# S32K144 register map
Vendor: NXP; Series: S32K; File version: 1.6
CPU: CM4 r0p1, little endian, MPU, FPU, 4 interrupt priority bits
Registers are 32-bit, read-write, reset 0x0 unless marked. A register's access mark holds for its fields unless they carry their own. Offsets are from the block's base; [hi:lo] are bit positions; {n}, {i} and the like mark numbered series; 'fields as' and 'values as' point back to an identical list.

## CAN0 — Flex Controller Area Network module
Base 0x40024000; register names take the prefix CAN0_
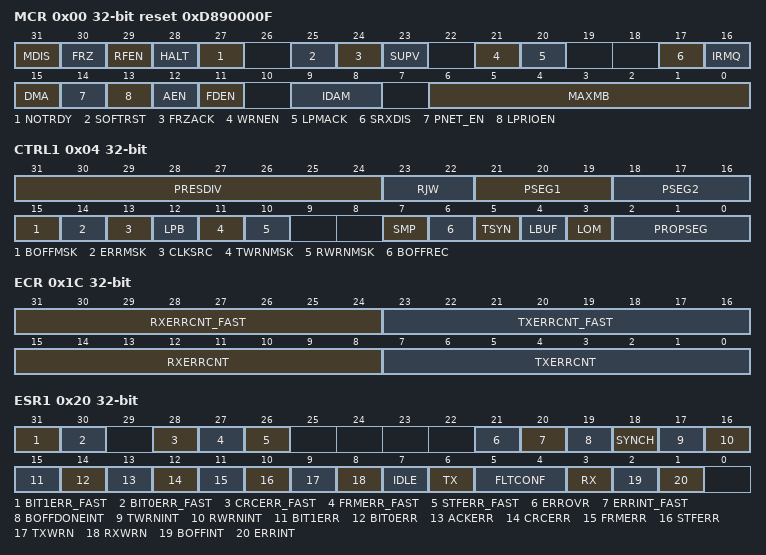
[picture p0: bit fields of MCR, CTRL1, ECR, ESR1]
0x00 MCR reset 0xD890000F — Module Configuration Register
  [31] MDIS — Module Disable
    0=Enable the FlexCAN module; 1=Disable the FlexCAN module
  [30] FRZ — Freeze Enable
    0=Not enabled to enter Freeze mode; 1=Enabled to enter Freeze mode
  [29] RFEN — Rx FIFO Enable
    0=Rx FIFO not enabled; 1=Rx FIFO enabled
  [28] HALT — Halt FlexCAN
    0=No Freeze mode request; 1=Enters Freeze mode if the FRZ bit is asserted
  [27] NOTRDY ro — FlexCAN Not Ready
    0=FlexCAN module is either in Normal mode, Listen-Only mode or Loop-Back mode
  [25] SOFTRST — Soft Reset
    0=No reset request; 1=Resets the registers affected by soft reset
  [24] FRZACK ro — Freeze Mode Acknowledge
    0=FlexCAN not in Freeze mode, prescaler running; 1=FlexCAN in Freeze mode, prescaler stopped
  [23] SUPV — Supervisor Mode
  [21] WRNEN — Warning Interrupt Enable
    0=TWRNINT and RWRNINT bits are zero, independent of the values in the error counters; 1=TWRNINT and RWRNINT bits are set when the respective error counter transitions from less than 96 to greater than or equal to 96
  [20] LPMACK ro — Low-Power Mode Acknowledge
    0=FlexCAN is not in a low-power mode; 1=FlexCAN is in a low-power mode
  [17] SRXDIS — Self Reception Disable
    0=Self reception enabled; 1=Self reception disabled
  [16] IRMQ — Individual Rx Masking And Queue Enable
    0=Individual Rx masking and queue feature are disabled. For backward compatibility with legacy applications, the reading of C/S word locks the MB even if it is EMPTY.; 1=Individual Rx masking and queue feature are enabled
  [15] DMA — DMA Enable
    0=DMA feature for RX FIFO disabled; 1=DMA feature for RX FIFO enabled
  [14] PNET_EN — Pretended Networking Enable
    0=Pretended Networking mode is disabled; 1=Pretended Networking mode is enabled
  [13] LPRIOEN — Local Priority Enable
    0=Local Priority disabled; 1=Local Priority enabled
  [12] AEN — Abort Enable
    0=Abort disabled; 1=Abort enabled
  [11] FDEN — CAN FD operation enable
    1=CAN FD is enabled. FlexCAN is able to receive and transmit messages in both CAN FD and CAN 2.0 formats.; 0=CAN FD is disabled. FlexCAN is able to receive and transmit messages in CAN 2.0 format.
  [9:8] IDAM — ID Acceptance Mode
    0=Format A: One full ID (standard and extended) per ID Filter Table element; 1=Format B: Two full standard IDs or two partial 14-bit (standard and extended) IDs per ID Filter Table element; 2=Format C: Four partial 8-bit Standard IDs per ID Filter Table element; 3=Format D: All frames rejected
  [6:0] MAXMB — Number Of The Last Message Buffer
0x04 CTRL1 — Control 1 register
  [31:24] PRESDIV — Prescaler Division Factor
  [23:22] RJW — Resync Jump Width
  [21:19] PSEG1 — Phase Segment 1
  [18:16] PSEG2 — Phase Segment 2
  [15] BOFFMSK — Bus Off Interrupt Mask
    0=Bus Off interrupt disabled; 1=Bus Off interrupt enabled
  [14] ERRMSK — Error Interrupt Mask
    0=Error interrupt disabled; 1=Error interrupt enabled
  [13] CLKSRC — CAN Engine Clock Source
    0=The CAN engine clock source is the oscillator clock. Under this condition, the oscillator clock frequency must be lower than the bus clock.; 1=The CAN engine clock source is the peripheral clock
  [12] LPB — Loop Back Mode
    0=Loop Back disabled; 1=Loop Back enabled
  [11] TWRNMSK — Tx Warning Interrupt Mask
    0=Tx Warning Interrupt disabled; 1=Tx Warning Interrupt enabled
  [10] RWRNMSK — Rx Warning Interrupt Mask
    0=Rx Warning Interrupt disabled; 1=Rx Warning Interrupt enabled
  [7] SMP — CAN Bit Sampling
    0=Just one sample is used to determine the bit value; 1=Three samples are used to determine the value of the received bit: the regular one (sample point) and 2 preceding samples; a majority rule is used
  [6] BOFFREC — Bus Off Recovery
    0=Automatic recovering from Bus Off state enabled; 1=Automatic recovering from Bus Off state disabled
  [5] TSYN — Timer Sync
    0=Timer Sync feature disabled; 1=Timer Sync feature enabled
  [4] LBUF — Lowest Buffer Transmitted First
    0=Buffer with highest priority is transmitted first; 1=Lowest number buffer is transmitted first
  [3] LOM — Listen-Only Mode
    0=Listen-Only mode is deactivated; 1=FlexCAN module operates in Listen-Only mode
  [2:0] PROPSEG — Propagation Segment
0x08 TIMER — Free Running Timer
  [15:0] TIMER — Timer Value
0x10 RXMGMASK reset not defined — Rx Mailboxes Global Mask Register
  [31:0] MG — Rx Mailboxes Global Mask Bits
0x14 RX14MASK reset not defined
  [31:0] RX14M — Rx Buffer 14 Mask Bits
0x18 RX15MASK reset not defined
  [31:0] RX15M — Rx Buffer 15 Mask Bits
0x1C ECR — Error Counter
  [31:24] RXERRCNT_FAST — Receive Error Counter for fast bits
  [23:16] TXERRCNT_FAST — Transmit Error Counter for fast bits
  [15:8] RXERRCNT — Receive Error Counter
  [7:0] TXERRCNT — Transmit Error Counter
0x20 ESR1 — Error and Status 1 register
  [31] BIT1ERR_FAST ro — Bit1 Error in the Data Phase of CAN FD frames with the BRS bit set
    0=No such occurrence; 1=At least one bit sent as recessive is received as dominant
  [30] BIT0ERR_FAST ro — Bit0 Error in the Data Phase of CAN FD frames with the BRS bit set
    0=No such occurrence; 1=At least one bit sent as dominant is received as recessive
  [28] CRCERR_FAST ro — Cyclic Redundancy Check Error in the CRC field of CAN FD frames with the BRS bit set
    0=No such occurrence; 1=A CRC error occurred since last read of this register
  [27] FRMERR_FAST ro — Form Error in the Data Phase of CAN FD frames with the BRS bit set
    0=No such occurrence; 1=A Form Error occurred since last read of this register
  [26] STFERR_FAST ro — Stuffing Error in the Data Phase of CAN FD frames with the BRS bit set
    0=No such occurrence; 1=A Stuffing Error occurred since last read of this register
  [21] ERROVR — Error Overrun bit
    0=Overrun has not occurred; 1=Overrun has occurred
  [20] ERRINT_FAST — Error Interrupt for errors detected in the Data Phase of CAN FD frames with the BRS bit set
    0=No such occurrence; 1=Indicates setting of any Error Bit detected in the Data Phase of CAN FD frames with the BRS bit set
  [19] BOFFDONEINT — Bus Off Done Interrupt
    0=No such occurrence; 1=FlexCAN module has completed Bus Off process
  [18] SYNCH ro — CAN Synchronization Status
    0=FlexCAN is not synchronized to the CAN bus; 1=FlexCAN is synchronized to the CAN bus
  [17] TWRNINT — Tx Warning Interrupt Flag
    0=No such occurrence; 1=The Tx error counter transitioned from less than 96 to greater than or equal to 96
  [16] RWRNINT — Rx Warning Interrupt Flag
    0=No such occurrence; 1=The Rx error counter transitioned from less than 96 to greater than or equal to 96
  [15] BIT1ERR ro — Bit1 Error
    values as BIT1ERR_FAST
  [14] BIT0ERR ro — Bit0 Error
    values as BIT0ERR_FAST
  [13] ACKERR ro — Acknowledge Error
    0=No such occurrence; 1=An ACK error occurred since last read of this register
  [12] CRCERR ro — Cyclic Redundancy Check Error
    values as CRCERR_FAST
  [11] FRMERR ro — Form Error
    values as FRMERR_FAST
  [10] STFERR ro — Stuffing Error
    values as STFERR_FAST
  [9] TXWRN ro — TX Error Warning
    0=No such occurrence; 1=TXERRCNT is greater than or equal to 96
  [8] RXWRN ro — Rx Error Warning
    0=No such occurrence; 1=RXERRCNT is greater than or equal to 96
  [7] IDLE ro
    0=No such occurrence; 1=CAN bus is now IDLE
  [6] TX ro — FlexCAN In Transmission
    0=FlexCAN is not transmitting a message; 1=FlexCAN is transmitting a message
  [5:4] FLTCONF ro — Fault Confinement State
    0=Error Active; 1=Error Passive; 0b1x=Bus Off
  [3] RX ro — FlexCAN In Reception
    0=FlexCAN is not receiving a message; 1=FlexCAN is receiving a message
  [2] BOFFINT — Bus Off Interrupt
    0=No such occurrence; 1=FlexCAN module entered Bus Off state
  [1] ERRINT — Error Interrupt
    0=No such occurrence; 1=Indicates setting of any Error Bit in the Error and Status Register
0x28 IMASK1 — Interrupt Masks 1 register
  [31:0] BUF31TO0M — Buffer MB i Mask
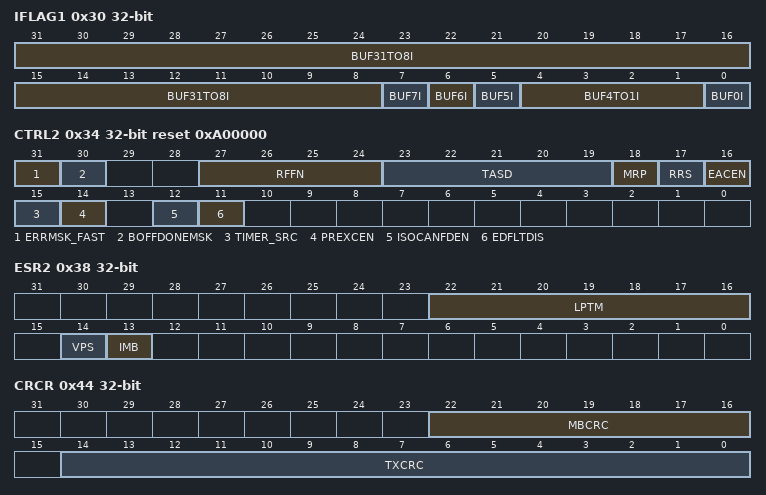
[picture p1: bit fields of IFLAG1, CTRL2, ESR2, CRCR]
0x30 IFLAG1 — Interrupt Flags 1 register
  [31:8] BUF31TO8I — Buffer MBi Interrupt
  [7] BUF7I — Buffer MB7 Interrupt Or "Rx FIFO Overflow"
    0=No occurrence of MB7 completing transmission/reception when MCR[RFEN]=0, or of Rx FIFO overflow when MCR[RFEN]=1; 1=MB7 completed transmission/reception when MCR[RFEN]=0, or Rx FIFO overflow when MCR[RFEN]=1
  [6] BUF6I — Buffer MB6 Interrupt Or "Rx FIFO Warning"
    0=No occurrence of MB6 completing transmission/reception when MCR[RFEN]=0, or of Rx FIFO almost full when MCR[RFEN]=1; 1=MB6 completed transmission/reception when MCR[RFEN]=0, or Rx FIFO almost full when MCR[RFEN]=1
  [5] BUF5I — Buffer MB5 Interrupt Or "Frames available in Rx FIFO"
    0=No occurrence of MB5 completing transmission/reception when MCR[RFEN]=0, or of frame(s) available in the FIFO, when MCR[RFEN]=1; 1=MB5 completed transmission/reception when MCR[RFEN]=0, or frame(s) available in the Rx FIFO when MCR[RFEN]=1. It generates a DMA request in case of MCR[RFEN] and MCR[DMA] are enabled.
  [4:1] BUF4TO1I — Buffer MB i Interrupt Or "reserved"
  [0] BUF0I — Buffer MB0 Interrupt Or Clear FIFO bit
    0=The corresponding buffer has no occurrence of successfully completed transmission or reception when MCR[RFEN]=0; 1=The corresponding buffer has successfully completed transmission or reception when MCR[RFEN]=0
0x34 CTRL2 reset 0xA00000 — Control 2 register
  [31] ERRMSK_FAST — Error Interrupt Mask for errors detected in the Data Phase of fast CAN FD frames
    0=ERRINT_FAST Error interrupt disabled; 1=ERRINT_FAST Error interrupt enabled
  [30] BOFFDONEMSK — Bus Off Done Interrupt Mask
    0=Bus Off Done interrupt disabled; 1=Bus Off Done interrupt enabled
  [27:24] RFFN — Number Of Rx FIFO Filters
  [23:19] TASD — Tx Arbitration Start Delay
  [18] MRP — Mailboxes Reception Priority
    0=Matching starts from Rx FIFO and continues on Mailboxes; 1=Matching starts from Mailboxes and continues on Rx FIFO
  [17] RRS — Remote Request Storing
    0=Remote Response Frame is generated; 1=Remote Request Frame is stored
  [16] EACEN — Entire Frame Arbitration Field Comparison Enable For Rx Mailboxes
    0=Rx Mailbox filter's IDE bit is always compared and RTR is never compared despite mask bits; 1=Enables the comparison of both Rx Mailbox filter's IDE and RTR bit with their corresponding bits within the incoming frame. Mask bits do apply.
  [15] TIMER_SRC — Timer Source
    0=The Free Running Timer is clocked by the CAN bit clock, which defines the baud rate on the CAN bus; 1=The Free Running Timer is clocked by an external time tick. The period can be either adjusted to be equal to the baud rate on the CAN bus, or a different value as required. See the device specific section for details about the external time tick.
  [14] PREXCEN — Protocol Exception Enable
    0=Protocol Exception is disabled; 1=Protocol Exception is enabled
  [12] ISOCANFDEN — ISO CAN FD Enable
    0=FlexCAN operates using the non-ISO CAN FD protocol; 1=FlexCAN operates using the ISO CAN FD protocol (ISO 11898-1)
  [11] EDFLTDIS — Edge Filter Disable
    0=Edge Filter is enabled; 1=Edge Filter is disabled
0x38 ESR2 ro — Error and Status 2 register
  [22:16] LPTM — Lowest Priority Tx Mailbox
  [14] VPS — Valid Priority Status
    0=Contents of IMB and LPTM are invalid; 1=Contents of IMB and LPTM are valid
  [13] IMB — Inactive Mailbox
    0=If ESR2[VPS] is asserted, the ESR2[LPTM] is not an inactive Mailbox; 1=If ESR2[VPS] is asserted, there is at least one inactive Mailbox. LPTM content is the number of the first one.
0x44 CRCR ro — CRC Register
  [22:16] MBCRC — CRC Mailbox
  [14:0] TXCRC — Transmitted CRC value
0x48 RXFGMASK reset not defined — Rx FIFO Global Mask register
  [31:0] FGM — Rx FIFO Global Mask Bits
0x4C RXFIR ro reset not defined — Rx FIFO Information Register
  [8:0] IDHIT — Identifier Acceptance Filter Hit Indicator
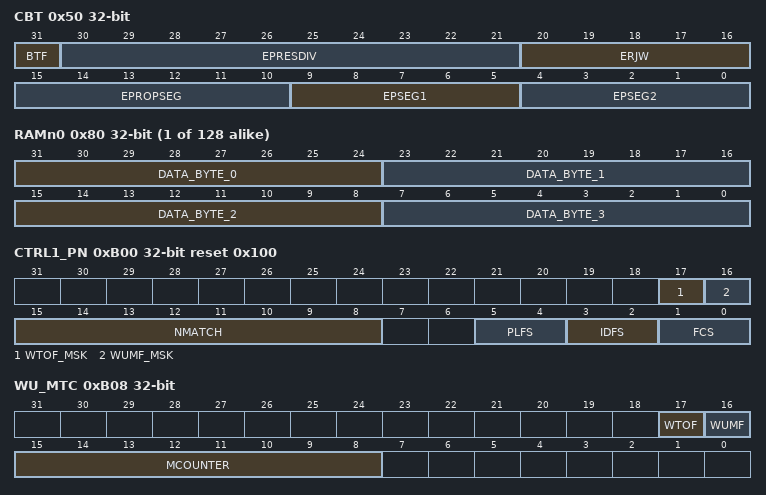
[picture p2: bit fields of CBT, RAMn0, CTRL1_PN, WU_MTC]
0x50 CBT — CAN Bit Timing Register
  [31] BTF — Bit Timing Format Enable
    0=Extended bit time definitions disabled; 1=Extended bit time definitions enabled
  [30:21] EPRESDIV — Extended Prescaler Division Factor
  [20:16] ERJW — Extended Resync Jump Width
  [15:10] EPROPSEG — Extended Propagation Segment
  [9:5] EPSEG1 — Extended Phase Segment 1
  [4:0] EPSEG2 — Extended Phase Segment 2
{0x80+4i} RAMn{i} (i=0..127) — Embedded RAM
  [31-8n:24-8n] DATA_BYTE_{n} (n=0..3) — Data byte {n} of Rx/Tx frame.
{0x880+4i} RXIMR{i} reset not defined (i=0..31) — Rx Individual Mask Registers
  [31:0] MI — Individual Mask Bits
0xB00 CTRL1_PN reset 0x100 — Pretended Networking Control 1 Register
  [17] WTOF_MSK — Wake Up by Timeout Flag Mask Bit
    0=Timeout wake up event is disabled; 1=Timeout wake up event is enabled
  [16] WUMF_MSK — Wake Up by Match Flag Mask Bit
    0=Wake up match event is disabled; 1=Wake up match event is enabled
  [15:8] NMATCH — Number of Messages Matching the Same Filtering Criteria
    1=Received message must match the predefined filtering criteria for ID and/or PL once before generating a wake up event; 2=Received message must match the predefined filtering criteria for ID and/or PL twice before generating a wake up event; 255=Received message must match the predefined filtering criteria for ID and/or PL 255 times before generating a wake up event
  [5:4] PLFS — Payload Filtering Selection
    0=Match upon a payload contents against an exact target value; 1=Match upon a payload value greater than or equal to a specified target value; 2=Match upon a payload value smaller than or equal to a specified target value; 3=Match upon a payload value inside a range, greater than or equal to a specified lower limit and smaller than or equal a specified upper limit
  [3:2] IDFS — ID Filtering Selection
    0=Match upon a ID contents against an exact target value; 1=Match upon a ID value greater than or equal to a specified target value; 2=Match upon a ID value smaller than or equal to a specified target value; 3=Match upon a ID value inside a range, greater than or equal to a specified lower limit and smaller than or equal a specified upper limit
  [1:0] FCS — Filtering Combination Selection
    0=Message ID filtering only; 1=Message ID filtering and payload filtering; 2=Message ID filtering occurring a specified number of times; 3=Message ID filtering and payload filtering a specified number of times
0xB04 CTRL2_PN — Pretended Networking Control 2 Register
  [15:0] MATCHTO — Timeout for No Message Matching the Filtering Criteria
0xB08 WU_MTC — Pretended Networking Wake Up Match Register
  [17] WTOF — Wake Up by Timeout Flag Bit
    0=No wake up by timeout event detected; 1=Wake up by timeout event detected
  [16] WUMF — Wake Up by Match Flag Bit
    0=No wake up by match event detected; 1=Wake up by match event detected
  [15:8] MCOUNTER ro — Number of Matches while in Pretended Networking
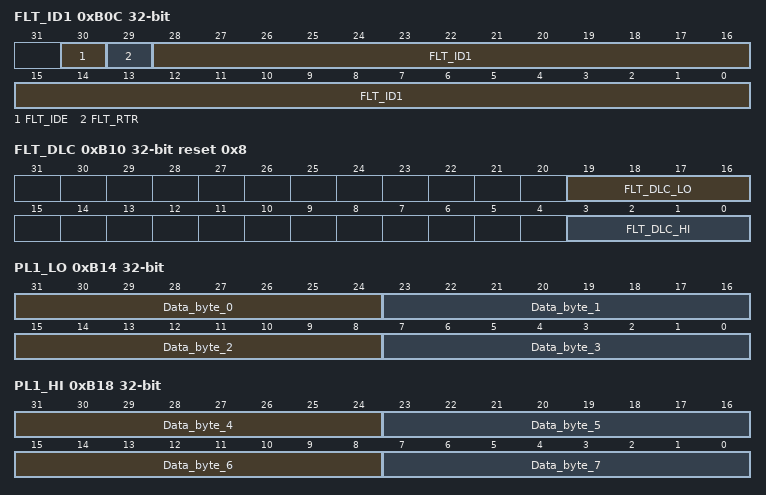
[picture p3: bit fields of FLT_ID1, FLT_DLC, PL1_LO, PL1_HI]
0xB0C FLT_ID1 — Pretended Networking ID Filter 1 Register
  [30] FLT_IDE — ID Extended Filter
    0=Accept standard frame format; 1=Accept extended frame format
  [29] FLT_RTR — Remote Transmission Request Filter
    0=Reject remote frame (accept data frame); 1=Accept remote frame
  [28:0] FLT_ID1 — ID Filter 1 for Pretended Networking filtering
0xB10 FLT_DLC reset 0x8 — Pretended Networking DLC Filter Register
  [19:16] FLT_DLC_LO — Lower Limit for Length of Data Bytes Filter
  [3:0] FLT_DLC_HI — Upper Limit for Length of Data Bytes Filter
0xB14 PL1_LO — Pretended Networking Payload Low Filter 1 Register
  [31-8n:24-8n] Data_byte_{n} (n=0..3) — Payload Filter 1 low order bits for Pretended Networking payload filtering corresponding to the data byte {n}.
0xB18 PL1_HI — Pretended Networking Payload High Filter 1 Register
  [63-8n:56-8n] Data_byte_{n} (n=4..7) — Payload Filter 1 high order bits for Pretended Networking payload filtering corresponding to the data byte {n}.
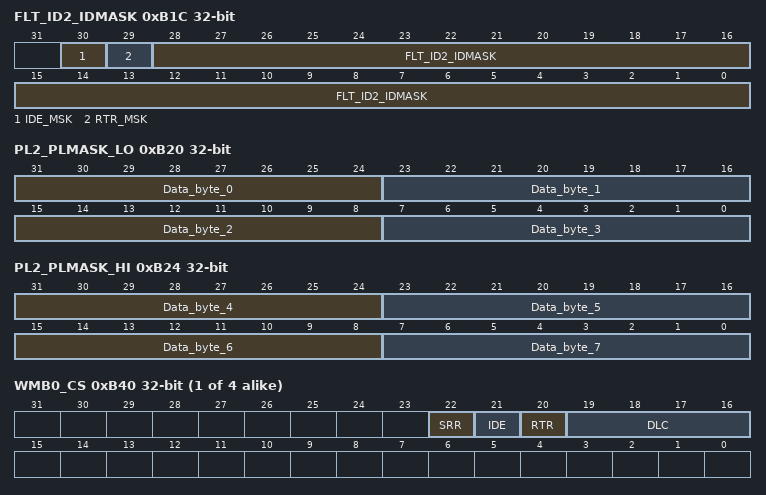
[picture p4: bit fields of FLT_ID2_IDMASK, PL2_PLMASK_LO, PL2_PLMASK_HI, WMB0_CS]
0xB1C FLT_ID2_IDMASK — Pretended Networking ID Filter 2 Register / ID Mask Register
  [30] IDE_MSK — ID Extended Mask Bit
    0=The corresponding bit in the filter is "don't care"; 1=The corresponding bit in the filter is checked
  [29] RTR_MSK — Remote Transmission Request Mask Bit
    values as IDE_MSK
  [28:0] FLT_ID2_IDMASK — ID Filter 2 for Pretended Networking Filtering / ID Mask Bits for Pretended Networking ID Filtering
0xB20 PL2_PLMASK_LO — Pretended Networking Payload Low Filter 2 Register / Payload Low Mask Register
  [31-8n:24-8n] Data_byte_{n} (n=0..3) — Payload Filter 2 low order bits / Payload Mask low order bits for Pretended Networking payload filtering corresponding to the data byte {n}.
0xB24 PL2_PLMASK_HI — Pretended Networking Payload High Filter 2 low order bits / Payload High Mask Register
  [63-8n:56-8n] Data_byte_{n} (n=4..7) — Payload Filter 2 high order bits / Payload Mask high order bits for Pretended Networking payload filtering corresponding to the data byte {n}.
{0xB40+0x10*i} WMB{i}_CS ro (i=0..3) — Wake Up Message Buffer Register for C/S
  [22] SRR — Substitute Remote Request
  [21] IDE — ID Extended Bit
    0=Frame format is standard; 1=Frame format is extended
  [20] RTR — Remote Transmission Request Bit
    0=Frame is data one (not remote); 1=Frame is a remote one
  [19:16] DLC — Length of Data in Bytes
{0xB44+0x10*i} WMB{i}_ID ro (i=0..3) — Wake Up Message Buffer Register for ID
  [28:0] ID — Received ID under Pretended Networking mode
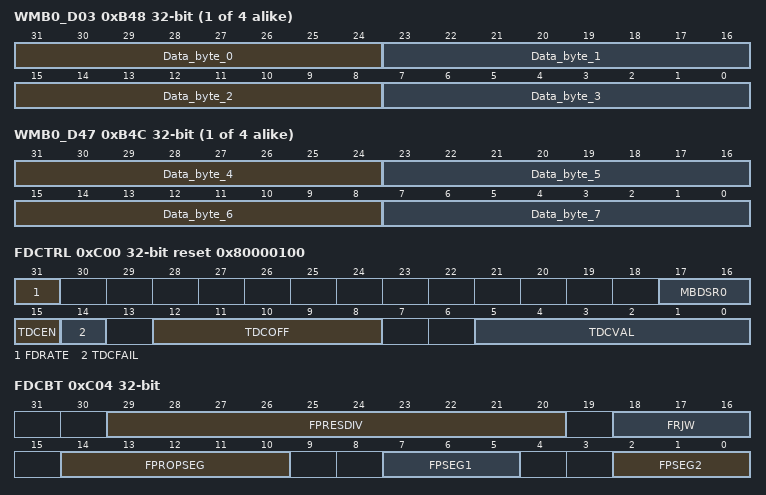
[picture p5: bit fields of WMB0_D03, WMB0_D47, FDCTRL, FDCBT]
{0xB48+0x10*i} WMB{i}_D03 ro (i=0..3) — Wake Up Message Buffer Register for Data 0-3
  [31-8n:24-8n] Data_byte_{n} (n=0..3) — Received payload corresponding to the data byte {n} under Pretended Networking mode
{0xB4C+0x10*i} WMB{i}_D47 ro (i=0..3) — Wake Up Message Buffer Register Data 4-7
  [63-8n:56-8n] Data_byte_{n} (n=4..7) — Received payload corresponding to the data byte {n} under Pretended Networking mode
0xC00 FDCTRL reset 0x80000100 — CAN FD Control Register
  [31] FDRATE — Bit Rate Switch Enable
    0=Transmit a frame in nominal rate. The BRS bit in the Tx MB has no effect.; 1=Transmit a frame with bit rate switching if the BRS bit in the Tx MB is recessive
  [17:16] MBDSR0 — Message Buffer Data Size for Region 0
    0=Selects 8 bytes per Message Buffer; 1=Selects 16 bytes per Message Buffer; 2=Selects 32 bytes per Message Buffer; 3=Selects 64 bytes per Message Buffer
  [15] TDCEN — Transceiver Delay Compensation Enable
    0=TDC is disabled; 1=TDC is enabled
  [14] TDCFAIL — Transceiver Delay Compensation Fail
    0=Measured loop delay is in range; 1=Measured loop delay is out of range
  [12:8] TDCOFF — Transceiver Delay Compensation Offset
  [5:0] TDCVAL ro — Transceiver Delay Compensation Value
0xC04 FDCBT — CAN FD Bit Timing Register
  [29:20] FPRESDIV — Fast Prescaler Division Factor
  [18:16] FRJW — Fast Resync Jump Width
  [14:10] FPROPSEG — Fast Propagation Segment
  [7:5] FPSEG1 — Fast Phase Segment 1
  [2:0] FPSEG2 — Fast Phase Segment 2
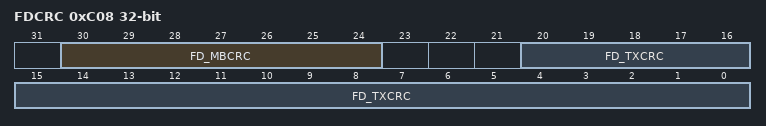
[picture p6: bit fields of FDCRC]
0xC08 FDCRC ro — CAN FD CRC Register
  [30:24] FD_MBCRC — CRC Mailbox Number for FD_TXCRC
  [20:0] FD_TXCRC — Extended Transmitted CRC value

## CAN1 — Flex Controller Area Network module
Base 0x40025000; register names take the prefix CAN1_
Registers as CAN0, without RAMn{n} (n=64..127), RXIMR{n} (n=16..31).

## CAN2 — Flex Controller Area Network module
Base 0x4002B000; register names take the prefix CAN2_
Registers as CAN0, without RAMn{n} (n=64..127), RXIMR{n} (n=16..31).

## Notices in the file
Redistribution and use in source and binary forms, with or without modification,
are permitted provided that the following conditions are met:
o Redistributions of source code must retain the above copyright notice, this list
of conditions and the following disclaimer.
o Redistributions in binary form must reproduce the above copyright notice, this
list of conditions and the following disclaimer in the documentation and/or
other materials provided with the distribution.
o Neither the name of Freescale Semiconductor, Inc. nor the names of its
contributors may be used to endorse or promote products derived from this
software without specific prior written permission.
THIS SOFTWARE IS PROVIDED BY THE COPYRIGHT HOLDERS AND CONTRIBUTORS "AS IS" AND
ANY EXPRESS OR IMPLIED WARRANTIES, INCLUDING, BUT NOT LIMITED TO, THE IMPLIED
WARRANTIES OF MERCHANTABILITY AND FITNESS FOR A PARTICULAR PURPOSE ARE
DISCLAIMED. IN NO EVENT SHALL THE COPYRIGHT HOLDER OR CONTRIBUTORS BE LIABLE FOR
ANY DIRECT, INDIRECT, INCIDENTAL, SPECIAL, EXEMPLARY, OR CONSEQUENTIAL DAMAGES
(INCLUDING, BUT NOT LIMITED TO, PROCUREMENT OF SUBSTITUTE GOODS OR SERVICES;
LOSS OF USE, DATA, OR PROFITS; OR BUSINESS INTERRUPTION) HOWEVER CAUSED AND ON
ANY THEORY OF LIABILITY, WHETHER IN CONTRACT, STRICT LIABILITY, OR TORT
(INCLUDING NEGLIGENCE OR OTHERWISE) ARISING IN ANY WAY OUT OF THE USE OF THIS
SOFTWARE, EVEN IF ADVISED OF THE POSSIBILITY OF SUCH DAMAGE.
